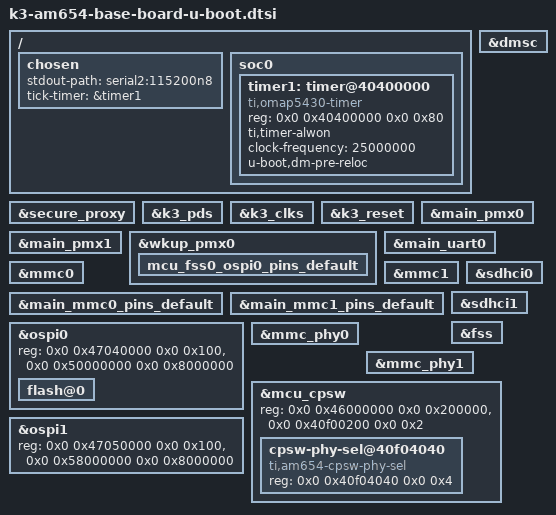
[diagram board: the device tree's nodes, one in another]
// SPDX-License-Identifier: GPL-2.0
/*
 * Copyright (C) 2016-2018 Texas Instruments Incorporated - http://www.ti.com/
 */

/ {
	chosen {
		stdout-path = "serial2:115200n8";
		tick-timer = &timer1;
	};

	soc0 {
		u-boot,dm-spl;

		timer1: timer@40400000 {
			compatible = "ti,omap5430-timer";
			reg = <0x0 0x40400000 0x0 0x80>;
			ti,timer-alwon;
			clock-frequency = <25000000>;
			u-boot,dm-pre-reloc;
		};
	};
};

&secure_proxy {
	u-boot,dm-spl;
};

&dmsc {
	u-boot,dm-spl;
};

&k3_pds {
	u-boot,dm-spl;
};

&k3_clks {
	u-boot,dm-spl;
};

&k3_reset {
	u-boot,dm-spl;
};

&main_pmx0 {
	u-boot,dm-spl;
};

&main_pmx1 {
	u-boot,dm-spl;
};

&wkup_pmx0 {
	u-boot,dm-spl;

	mcu_fss0_ospi0_pins_default {
		u-boot,dm-spl;
	};
};

&main_uart0 {
	u-boot,dm-spl;
};

&mmc0 {
	u-boot,dm-spl;
};

&mmc1 {
	u-boot,dm-spl;
};

&main_mmc0_pins_default {
	u-boot,dm-spl;
};

&main_mmc1_pins_default {
	u-boot,dm-spl;
};

&sdhci0 {
	u-boot,dm-spl;
};

&sdhci1 {
	u-boot,dm-spl;
};

&fss {
	u-boot,dm-spl;
};

&ospi0 {
	u-boot,dm-spl;

	 flash@0{
		u-boot,dm-spl;
	};
};

&mmc_phy0 {
	u-boot,dm-spl;
};

&mmc_phy1 {
	u-boot,dm-spl;
};

&mcu_cpsw {
	reg = <0x0 0x46000000 0x0 0x200000>,
	      <0x0 0x40f00200 0x0 0x2>;
	reg-names = "cpsw_nuss", "mac_efuse";

	cpsw-phy-sel@40f04040 {
		compatible = "ti,am654-cpsw-phy-sel";
		reg= <0x0 0x40f04040 0x0 0x4>;
		reg-names = "gmii-sel";
	};
};

&ospi0 {
	reg = <0x0 0x47040000 0x0 0x100>,
	      <0x0 0x50000000 0x0 0x8000000>;
};

&ospi1 {
	reg = <0x0 0x47050000 0x0 0x100>,
	      <0x0 0x58000000 0x0 0x8000000>;
};
